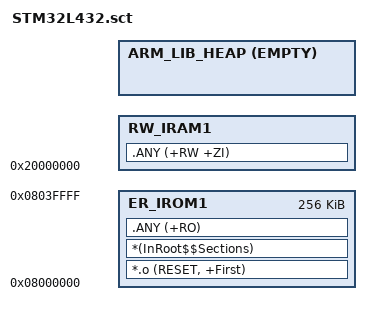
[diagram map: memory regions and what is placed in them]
; *************************************************************
; *** Scatter-Loading Description File generated by uVision ***
; *************************************************************

LR_IROM1 0x08000000 0x40000  {    ; load region size_region(256KB)
  ER_IROM1 0x08000000 0x40000  {  ; load address = execution address
   *.o (RESET, +First)
   *(InRoot$$Sections)
   .ANY (+RO)
  }
  RW_IRAM1 0x20000000 {  ; RW data
   .ANY (+RW +ZI)
  }
  ARM_LIB_HEAP +0 EMPTY 0x00010000-ImageLength(RW_IRAM1) ; Heap region, ram 64KB
  { }
  ScatterAssert(ImageLength(ARM_LIB_HEAP) > 0x1000)     ; Heap limit
}
